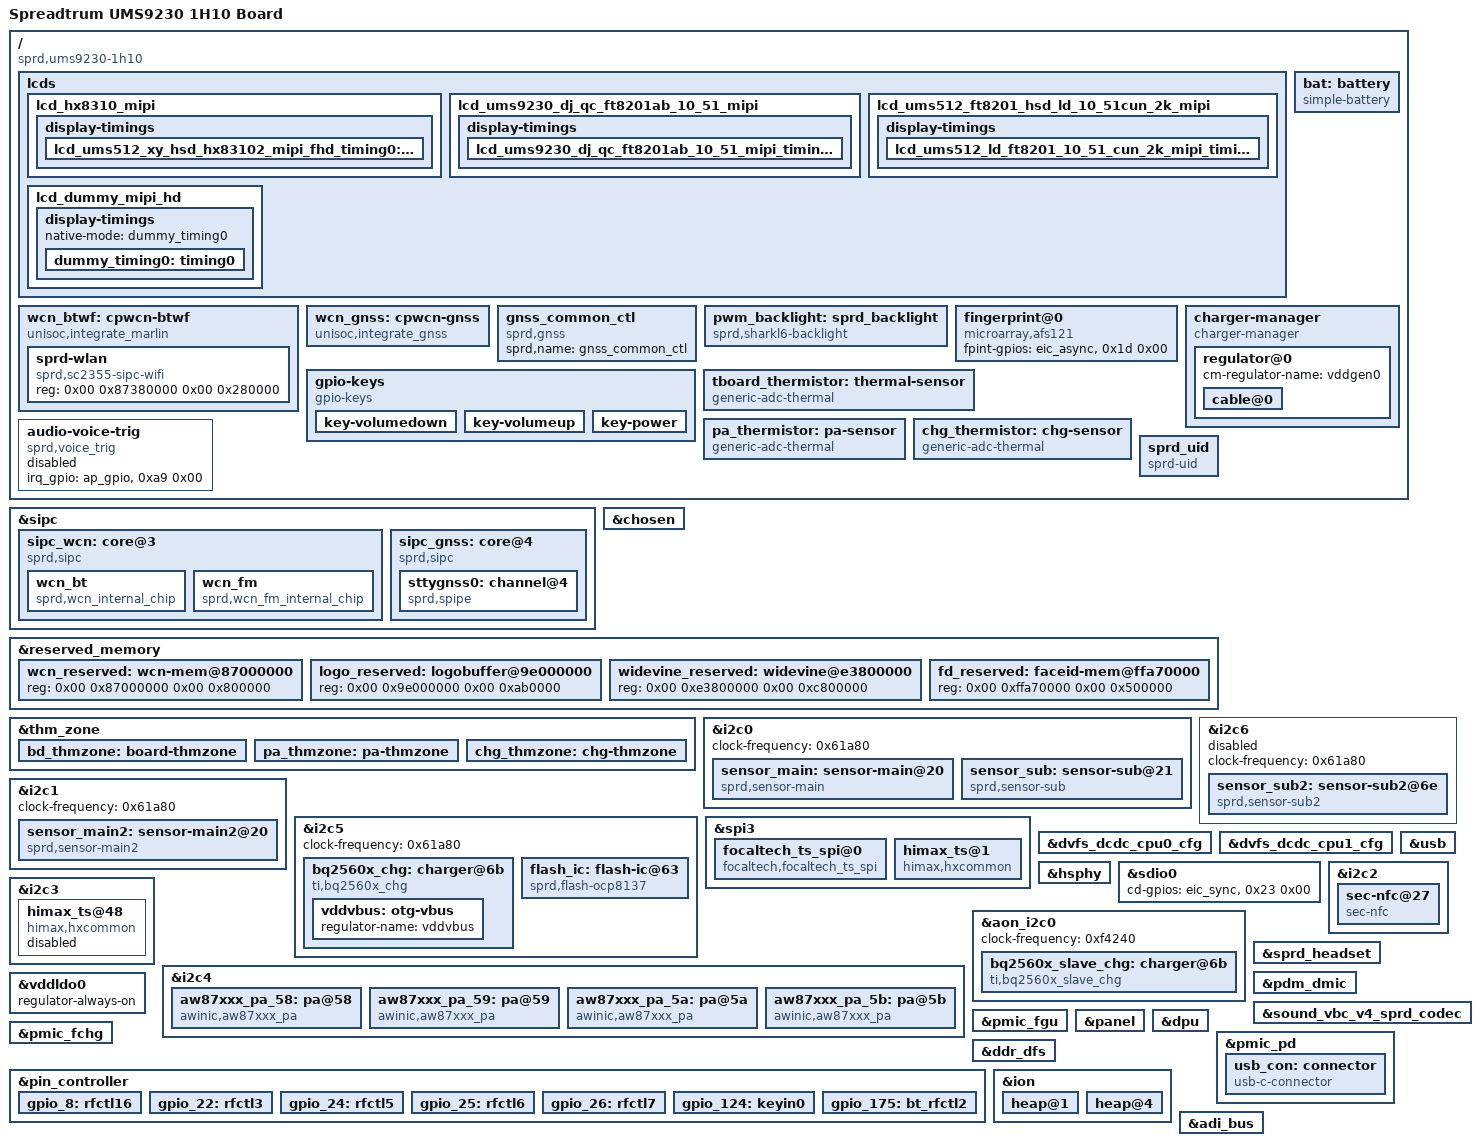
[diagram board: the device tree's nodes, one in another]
/dts-v1/;
/plugin/;

/ {
	model = "Spreadtrum UMS9230 1H10 Board";
	compatible = "sprd,ums9230-1h10";
	sprd,sc-id = "ums9230 1h10 1000";

	fragment {
		target-path = "/";

		__overlay__ {
			#address-cells = <0x02>;
			#size-cells = <0x02>;

			lcds {

				lcd_hx8310_mipi: lcd_hx8310_mipi {
					sprd,dsi-work-mode = <0x01>;
					sprd,dsi-lane-number = <0x04>;
					sprd,dsi-color-format = "rgb888";
					sprd,phy-bit-clock = <0xf32a0>;
					sprd,phy-escape-clock = <0x4e20>;
					sprd,width-mm = <0x87>;
					sprd,height-mm = <0xda>;
					sprd,esd-check-enable = <0x00>;
					sprd,esd-check-mode = <0x03>;
					sprd,esd-check-period = <0x3e8>;
					sprd,esd-check-register = <0x0a>;
					sprd,esd-check-value = <0x9c>;
					sprd,dpi-clk-div = <0x06>;
					sprd,video-lp-cmd-enable = <0x01>;
					sprd,hporch-lp-disable = <0x01>;
					sprd,use-dcs-write;
					sprd,reset-on-sequence = <0x01 0x0a 0x00 0x14 0x01 0x78>;
					sprd,reset-off-sequence = <0x00 0x14>;
					sprd,initial-command = [39 00 00 04 b9 83 10 2e 23 00 00 02 e2 03 23 00 00 02 e9 cd 23 00 00 02 bb 01 23 00 00 02 e9 00 39 00 00 05 d1 67 0c ff 05 39 00 00 12 b1 10 fa af af 31 31 b1 6b 31 36 36 36 36 22 21 15 00 39 00 00 11 b2 00 b0 47 80 00 26 e0 29 00 00 00 00 15 20 d7 00 39 00 00 11 b4 30 36 30 36 30 36 30 36 08 6f 07 58 00 ff 00 ff 39 00 00 03 d2 31 31 39 00 00 08 bf fc 85 80 9c 36 00 1c 39 00 00 2c d3 00 00 00 00 3c e8 00 00 00 37 37 33 0f 26 26 04 00 32 10 24 00 24 32 17 a8 07 a8 32 10 08 00 00 00 00 2b 50 b6 c8 2c 4f b6 c8 0f 39 00 00 2f e0 00 07 14 1b 23 40 58 5e 64 5f 76 7a 7d 8b 88 92 9c b2 b3 59 61 6c 73 00 07 14 1b 23 40 58 5e 64 5f 76 7a 7d 8b 88 92 9c b2 b3 59 61 6c 73 23 00 00 02 bd 01 39 00 00 0b cb 80 36 12 16 c0 28 40 84 02 34 39 00 00 0c d3 01 00 fc 00 00 11 10 00 0a 00 01 23 00 00 02 bd 02 39 00 00 07 b4 4e 00 33 11 33 88 39 00 00 04 bf f2 00 02 23 00 00 02 bd 00 39 00 00 0f c0 33 33 22 11 a2 17 00 80 00 00 08 00 63 63 39 00 00 2d d5 18 18 18 18 18 18 18 18 18 18 19 19 18 18 1a 1a 1b 1b 00 01 02 03 04 05 06 07 20 21 24 25 18 18 18 18 18 18 18 18 18 18 18 18 18 18 39 00 00 2d d6 18 18 18 18 18 18 18 18 18 18 18 18 19 19 1a 1a 1b 1b 07 06 05 04 03 02 01 00 25 24 21 20 18 18 18 18 18 18 18 18 18 18 18 18 18 18 39 00 00 04 d0 07 04 05 39 00 00 18 e7 12 13 02 02 55 00 0e 0e 00 26 29 72 1c 72 01 27 00 00 00 00 17 00 68 23 00 00 02 bd 01 39 00 00 08 e7 01 30 01 94 0d b5 0e 23 00 00 02 bd 02 39 00 00 1d e7 ff 01 fd 01 00 00 22 00 00 00 00 00 00 00 00 00 00 00 00 00 00 00 00 00 81 00 02 40 23 00 00 02 bd 00 39 00 00 0d d8 aa bb aa aa aa a0 aa bb aa aa aa a0 23 00 00 02 bd 02 39 00 00 0d d8 ff ff ff ff ff f0 ff ff ff ff ff f0 23 00 00 02 bd 03 39 00 00 19 d8 00 2a aa aa aa a0 00 2a aa aa aa a0 00 2a aa aa aa a0 00 2a aa aa aa a0 23 00 00 02 bd 00 39 00 00 09 ba 70 03 a8 83 f2 80 c0 0d 23 00 00 02 bd 03 23 00 00 02 b2 80 23 00 00 02 bd 00 39 00 00 07 c8 00 04 04 00 00 02 23 00 00 02 bd 00 39 00 00 06 cb 00 13 08 02 25 23 00 00 02 bd 02 39 00 00 06 cb 00 03 00 01 7e 23 00 00 02 bd 00 39 00 00 08 c7 30 b0 c2 08 10 42 04 23 00 00 02 bd 00 23 00 00 02 cc 0e 23 00 00 02 35 00 39 00 00 03 51 07 ff 39 00 00 04 c9 00 0e 10 23 00 00 02 53 2c 05 78 00 01 11 05 14 00 01 29];
					sprd,sleep-in-command = [13 0a 00 01 28 13 78 00 01 10];
					sprd,sleep-out-command = [13 78 00 01 11 13 64 00 01 29];
					phandle = <0x15>;

					display-timings {
						native-mode = <&lcd_ums512_xy_hsd_hx83102_mipi_fhd_timing0>;

						lcd_ums512_xy_hsd_hx83102_mipi_fhd_timing0: timing0 {
							clock-frequency = <0x9e4f580>;
							hactive = <0x4b0>;
							vactive = <0x780>;
							hback-porch = <0x10>;
							hfront-porch = <0x28>;
							vback-porch = <0x12>;
							vfront-porch = <0xe0>;
							hsync-len = <0x0c>;
							vsync-len = <0x0c>;
							phandle = <0x01>;
						};
					};
				};

				lcd_ums9230_dj_qc_ft8201ab_10_51_mipi: lcd_ums9230_dj_qc_ft8201ab_10_51_mipi {
					sprd,dsi-work-mode = <0x01>;
					sprd,dsi-lane-number = <0x04>;
					sprd,dsi-color-format = "rgb888";
					sprd,phy-bit-clock = <0xfee20>;
					sprd,phy-escape-clock = <0x4e20>;
					sprd,width-mm = <0x44>;
					sprd,height-mm = <0x79>;
					sprd,esd-check-enable = <0x00>;
					sprd,esd-check-mode = <0x03>;
					sprd,esd-check-period = <0x3e8>;
					sprd,esd-check-register = <0x0a>;
					sprd,esd-check-value = <0x9c>;
					sprd,dpi-clk-div = <0x06>;
					sprd,video-lp-cmd-enable = <0x01>;
					sprd,hporch-lp-disable = <0x01>;
					sprd,reset-on-sequence = <0x01 0x0a 0x00 0x14 0x01 0x64>;
					sprd,reset-off-sequence = <0x00 0x14>;
					sprd,use-dcs-write;
					sprd,initial-command = [23 00 00 02 00 00 39 00 00 04 ff 82 01 01 23 00 00 02 00 80 39 00 00 03 ff 82 01 23 00 00 02 00 93 23 00 00 02 c5 52 23 00 00 02 00 97 23 00 00 02 c5 52 23 00 00 02 00 9e 23 00 00 02 c5 05 23 00 00 02 00 9a 23 00 00 02 c5 e1 23 00 00 02 00 9c 23 00 00 02 c5 e1 23 00 00 02 00 b6 39 00 00 03 c5 43 43 23 00 00 02 00 b8 39 00 00 03 c5 57 57 23 00 00 02 00 00 39 00 00 03 d8 be be 23 00 00 02 00 00 39 00 00 04 d9 00 64 64 23 00 00 02 00 82 23 00 00 02 c5 95 23 00 00 02 00 83 23 00 00 02 c5 07 23 00 00 02 00 94 23 00 00 02 c5 46 23 00 00 02 00 98 23 00 00 02 c5 64 23 00 00 02 00 9b 23 00 00 02 c5 65 23 00 00 02 00 9d 23 00 00 02 c5 65 23 00 00 02 00 a0 23 00 00 02 a5 04 23 00 00 02 00 b0 39 00 00 04 ca 00 00 04 23 00 00 02 00 b4 23 00 00 02 ca 03 23 00 00 02 00 e6 23 00 00 02 c0 50 23 00 00 02 00 a7 23 00 00 02 f3 20 23 00 00 02 00 c1 23 00 00 02 c0 11 23 00 00 02 00 00 39 00 00 11 e1 05 0e 23 36 41 4d 5f 6e 71 7e 81 97 6c 59 5a 50 23 00 00 02 00 10 39 00 00 09 e1 49 3f 31 29 22 15 0d 13 23 00 00 02 00 00 39 00 00 11 e2 05 0e 23 36 41 4d 5f 6e 71 7e 81 97 6c 59 5a 50 23 00 00 02 00 10 39 00 00 09 e2 49 3f 31 29 22 15 0d 07 23 00 00 02 00 80 23 00 00 02 a4 8c 23 00 00 02 00 a0 23 00 00 02 f3 10 23 00 00 02 00 a1 39 00 00 03 b3 04 b0 23 00 00 02 00 a3 39 00 00 03 b3 07 80 23 00 00 02 00 a5 39 00 00 03 b3 80 13 23 00 00 02 00 d0 23 00 00 02 c1 b0 23 00 00 02 00 80 39 00 00 08 cb 3f 3f 3f 3f 3f 3f 3f 23 00 00 02 00 87 23 00 00 02 cb 3f 23 00 00 02 00 88 39 00 00 09 cb 3f 3f 3f 3f 3f 3f 3f 3f 23 00 00 02 00 90 39 00 00 08 cb 3f 3f 3f 3f 3f 3f 3f 23 00 00 02 00 97 23 00 00 02 cb 3f 23 00 00 02 00 98 39 00 00 09 cb d4 d4 d4 d4 d4 d4 d4 d4 23 00 00 02 00 a0 39 00 00 09 cb d4 d4 db d8 d4 d4 d4 d4 23 00 00 02 00 a8 39 00 00 09 cb d4 d4 d4 d4 d4 d4 d4 d4 23 00 00 02 00 b0 39 00 00 08 cb 00 00 00 00 00 00 00 23 00 00 02 00 b7 23 00 00 02 cb 00 23 00 00 02 00 b8 39 00 00 09 cb 00 00 00 00 00 00 00 00 23 00 00 02 00 c0 39 00 00 08 cb 00 00 00 00 00 00 00 23 00 00 02 00 c7 23 00 00 02 cb 00 23 00 00 02 00 d0 39 00 00 0b cb 00 00 30 30 00 30 30 30 00 30 23 00 00 02 00 80 39 00 00 09 cc 38 38 38 38 38 38 38 38 23 00 00 02 00 88 39 00 00 09 cc 2b 22 20 35 34 1a 18 16 23 00 00 02 00 90 39 00 00 07 cc 14 12 10 08 38 38 23 00 00 02 00 80 39 00 00 09 cd 38 38 38 38 38 38 38 38 23 00 00 02 00 88 39 00 00 09 cd 2b 21 1f 35 34 19 17 15 23 00 00 02 00 90 39 00 00 07 cd 13 11 0f 07 38 38 23 00 00 02 00 a0 39 00 00 09 cc 38 38 38 38 38 38 38 38 23 00 00 02 00 a8 39 00 00 09 cc 2b 21 07 35 34 0f 11 13 23 00 00 02 00 b0 39 00 00 07 cc 15 17 19 1f 38 38 23 00 00 02 00 a0 39 00 00 09 cd 38 38 38 38 38 38 38 38 23 00 00 02 00 a8 39 00 00 09 cd 2b 22 08 35 34 10 12 14 23 00 00 02 00 b0 39 00 00 07 cd 16 18 1a 20 38 38 23 00 00 02 00 81 23 00 00 02 c2 40 23 00 00 02 00 fd 23 00 00 02 cb 82 23 00 00 02 00 90 39 00 00 05 c2 85 03 1f 9f 23 00 00 02 00 94 39 00 00 05 c2 84 03 1f 9f 23 00 00 02 00 b0 39 00 00 05 c2 03 43 1f 9f 23 00 00 02 00 b4 39 00 00 05 c2 02 43 1f 9f 23 00 00 02 00 b8 39 00 00 05 c2 01 03 1f 9f 23 00 00 02 00 bc 39 00 00 05 c2 02 03 1f 9f 23 00 00 02 00 e0 39 00 00 09 c2 82 01 02 76 9f 00 00 0b 23 00 00 02 00 e8 39 00 00 09 c2 81 02 02 76 9f 00 00 0b 23 00 00 02 00 f0 39 00 00 09 c2 00 03 02 76 9f 00 00 0b 23 00 00 02 00 f8 39 00 00 09 c2 01 04 02 76 9f 00 00 0b 23 00 00 02 00 80 39 00 00 09 c3 02 05 02 76 9f 00 00 0b 23 00 00 02 00 88 39 00 00 09 c3 03 06 02 76 9f 00 00 0b 23 00 00 02 00 90 39 00 00 09 c3 04 07 02 76 9f 00 00 0b 23 00 00 02 00 98 39 00 00 09 c3 05 08 02 76 9f 00 00 0b 23 00 00 02 00 c0 39 00 00 09 cd 06 09 02 76 9f 00 00 0b 23 00 00 02 00 c8 39 00 00 09 cd 07 0a 02 76 9f 00 00 0b 23 00 00 02 00 d0 39 00 00 09 cd 08 0b 02 76 9f 00 00 0b 23 00 00 02 00 d8 39 00 00 09 cd 09 0c 02 76 9f 00 00 0b 23 00 00 02 00 f0 39 00 00 07 cc 3d 88 88 18 18 80 23 00 00 02 00 80 39 00 00 07 c0 00 96 01 0b 00 17 23 00 00 02 00 90 39 00 00 07 c0 00 96 01 0b 00 17 23 00 00 02 00 a0 39 00 00 07 c0 01 27 01 12 00 10 23 00 00 02 00 b0 39 00 00 06 c0 00 96 01 0b 17 23 00 00 02 00 a3 39 00 00 04 c1 22 22 04 23 00 00 02 00 80 23 00 00 02 ce 00 23 00 00 02 00 90 23 00 00 02 ce 00 23 00 00 02 00 d0 39 00 00 09 ce 01 00 18 01 01 00 ef 01 23 00 00 02 00 e0 23 00 00 02 ce 00 23 00 00 02 00 f0 23 00 00 02 ce 00 23 00 00 02 00 b0 39 00 00 05 cf 06 06 4c 50 23 00 00 02 00 b5 39 00 00 05 cf 03 03 bc c0 23 00 00 02 00 c0 39 00 00 05 cf 07 07 58 5c 23 00 00 02 00 c5 39 00 00 05 cf 00 07 08 80 23 00 00 02 00 90 23 00 00 02 c4 88 23 00 00 02 00 92 23 00 00 02 c4 c0 23 00 00 02 00 c5 39 00 00 04 c3 0e 00 10 23 00 00 02 00 c8 39 00 00 04 c3 0e 00 10 23 00 00 02 00 c9 23 00 00 02 ce 00 23 00 00 02 1c 00 23 00 00 02 00 d6 23 00 00 02 c1 00 23 00 00 02 00 d5 23 00 00 02 c0 f0 23 00 00 02 00 a0 23 00 00 02 c1 e0 23 00 00 02 00 9f 23 00 00 02 c5 00 23 00 00 02 00 91 23 00 00 02 c5 4c 23 00 00 02 00 d7 23 00 00 02 ce 01 23 00 00 02 00 82 23 00 00 02 a5 01 23 00 00 02 00 8c 39 00 00 03 cf 40 40 23 00 00 02 00 9a 23 00 00 02 f5 35 23 00 00 02 00 a2 23 00 00 02 f5 1f 23 00 00 02 00 b2 23 00 00 02 c5 15 23 00 00 02 00 b5 23 00 00 02 c5 05 23 00 00 02 00 d2 23 00 00 02 c5 d1 23 00 00 02 00 e0 39 00 00 05 c5 3c 3c fb fb 23 00 00 02 00 e8 39 00 00 05 c5 c1 14 09 07 23 00 00 02 00 ec 39 00 00 05 c5 00 00 00 00 23 00 00 02 00 f4 39 00 00 04 c5 00 01 01 23 00 00 02 00 fb 39 00 00 04 c5 01 01 01 23 00 00 02 00 f0 39 00 00 05 c5 3c 3c fb fb 23 00 00 02 00 f7 39 00 00 05 c5 3c 3c fb fb 23 00 00 02 00 a4 23 00 00 02 f3 0b 23 00 00 02 00 00 23 00 00 02 fa 02 23 00 00 02 00 a8 23 00 00 02 c5 09 23 00 00 02 00 cb 23 00 00 02 c5 01 23 00 00 02 00 b6 39 00 00 03 c5 43 43 23 00 00 02 00 b8 39 00 00 03 c5 57 57 23 00 00 02 00 91 23 00 00 02 a5 00 23 00 00 02 00 a4 23 00 00 02 f3 0b 23 00 00 02 00 00 23 00 00 02 fa 5a 23 00 00 02 00 a4 23 00 00 02 f3 0b 23 00 00 02 00 00 23 00 00 02 fa 01 23 00 00 02 00 a8 23 00 00 02 c5 09 23 00 00 02 00 cb 23 00 00 02 c5 09 23 00 00 02 00 b6 39 00 00 03 c5 41 41 23 00 00 02 00 b8 39 00 00 03 c5 55 55 23 00 00 02 00 91 23 00 00 02 a5 40 23 00 00 02 00 a4 23 00 00 02 f3 0b 23 00 00 02 00 00 23 00 00 02 fa 5a 23 00 00 02 00 00 39 00 00 04 ff 00 00 00 23 00 00 02 00 80 39 00 00 03 ff 00 00 13 78 00 01 11 13 14 00 01 29];
					sprd,sleep-in-command = [13 0a 00 01 28 13 78 00 01 10];
					sprd,sleep-out-command = [13 78 00 01 11 13 32 00 01 29];
					phandle = <0x16>;

					display-timings {
						native-mode = <&lcd_ums9230_dj_qc_ft8201ab_10_51_mipi_timing0>;

						lcd_ums9230_dj_qc_ft8201ab_10_51_mipi_timing0: timing0 {
							clock-frequency = <0xa5f0780>;
							hactive = <0x4b0>;
							vactive = <0x780>;
							hback-porch = <0x1c>;
							hfront-porch = <0x4c>;
							vback-porch = <0x28>;
							vfront-porch = <0xf4>;
							hsync-len = <0x08>;
							vsync-len = <0x06>;
							phandle = <0x02>;
						};
					};
				};

				lcd_ums512_ft8201_hsd_ld_10_51cun_2k_mipi: lcd_ums512_ft8201_hsd_ld_10_51cun_2k_mipi {
					sprd,dsi-work-mode = <0x01>;
					sprd,dsi-lane-number = <0x04>;
					sprd,dsi-color-format = "rgb888";
					sprd,phy-bit-clock = <0xe8e90>;
					sprd,phy-escape-clock = <0x4e20>;
					sprd,width-mm = <0x87>;
					sprd,height-mm = <0xda>;
					sprd,esd-check-enable = <0x00>;
					sprd,esd-check-mode = <0x03>;
					sprd,esd-check-period = <0x3e8>;
					sprd,esd-check-register = <0x0a>;
					sprd,esd-check-value = <0x9c>;
					sprd,dpi-clk-div = <0x06>;
					sprd,video-lp-cmd-enable = <0x01>;
					sprd,hporch-lp-disable = <0x01>;
					sprd,reset-on-sequence = <0x01 0x0a 0x00 0x14 0x01 0x64>;
					sprd,reset-off-sequence = <0x00 0x14>;
					sprd,use-dcs-write;
					sprd,initial-command = <0x23000002 0x3900 0x4ff82 0x1012300 0x20080 0x39000003 0xff820123 0x200 0x90390000 0xff54ad9 0x4ad92a2a 0x2b0b0c14 0x15393483 0x23000002 0xa03900 0xdf587 0x1618161f 0x97777746 0xc0d9e023 0x200 0x90390000 0x11c5840c 0x1664202 0x16b2701 0xcd25cd25 0x5402300 0x200d8 0x39000008 0xcd00000f 0xff000000 0x23000002 0xc42300 0x2cf00 0x23000002 0xc92300 0x2cf00 0x23000002 0x932300 0x2c57a 0x23000002 0x972300 0x2c57a 0x23000002 0x9e2300 0x2c50a 0x23000002 0x9a2300 0x2c539 0x23000002 0x9c2300 0x2c539 0x23000002 0xb63900 0x3c56b 0x6b230000 0x200b839 0x3c5 0x2f2f2300 0x20000 0x39000003 0xd8b4b423 0x200 0x82230000 0x2c59523 0x200 0x83230000 0x2c50723 0x200 0x390000 0x11e1050f 0x2437414d 0x5e6b6d78 0x798b7b6a 0x6b5f2300 0x20010 0x39000009 0xe1574b3b 0x31291906 0x230000 0x2000039 0x11e2 0x50f2437 0x414d5e6b 0x6d78798b 0x7b6a6b5f 0x23000002 0x103900 0x9e257 0x4b3b3129 0x19060023 0x200 0x80230000 0x2a40c23 0x200 0x84390000 0x3c50000 0x23000002 0xa02300 0x2f310 0x23000002 0xa13900 0x3b304 0xb0230000 0x200a339 0x3b3 0x7802300 0x200a5 0x39000003 0xb3801323 0x200 0xd0230000 0x2c1b023 0x200 0x80390000 0x8cb3333 0x30333033 0x30230000 0x2008723 0x2cb 0x33230000 0x2008839 0x9cb 0x33335555 0x33303333 0x23000002 0x903900 0x8cb30 0x33333330 0x30332300 0x20097 0x23000002 0xcb332300 0x20098 0x39000009 0xcb141414 0x14141414 0x14230000 0x200a039 0x9cb 0x14145555 0x14141414 0x23000002 0xa83900 0x9cb14 0x55551414 0x14141423 0x200 0xb0390000 0x8cb0000 0x00 0x230000 0x200b723 0x2cb 0x230000 0x200b839 0x9cb 0x5555 0x00 0x23000002 0xc03900 0x8cb00 0x55550000 0x2300 0x200c7 0x23000002 0xcb002300 0x20080 0x39000009 0xcc000000 0x292a 0x34230000 0x2008839 0x9cc 0x35131415 0x16071f00 0x23000002 0x903900 0x7cc00 0x00 0x230000 0x2008039 0x9cd 0x00 0x292a34 0x23000002 0x883900 0x9cd35 0x1718191a 0x8200023 0x200 0x90390000 0x7cd0000 0x00 0x23000002 0xa03900 0x9cc00 0x00 0x292a3423 0x200 0xa8390000 0x9cc351a 0x19181720 0x8002300 0x200b0 0x39000007 0xcc000000 0x23 0x200 0xa0390000 0x9cd0000 0x29 0x2a342300 0x200a8 0x39000009 0xcd351615 0x14131f07 0x230000 0x200b039 0x7cd 0x00 0x2300 0x20081 0x23000002 0xc2402300 0x20090 0x39000005 0xc2840278 0x9d230000 0x2009439 0x5c2 0x8302789d 0x23000002 0xb03900 0x5c200 0x2789d23 0x200 0xb4390000 0x5c20102 0x789d2300 0x20080 0x39000009 0xc3828702 0x7cb20002 0x7230000 0x2008839 0x9c3 0x85027c 0xb2000207 0x23000002 0x903900 0x9c302 0x83027cb2 0x20723 0x200 0x98390000 0x9c30481 0x27cb200 0x2072300 0x200c0 0x39000009 0xcd818602 0x7cb20002 0x7230000 0x200c839 0x9cd 0x184027c 0xb2000207 0x23000002 0xd03900 0x9cd03 0x82027cb2 0x20723 0x200 0xd8390000 0x9cd0580 0x27cb200 0x2072300 0x200e2 0x39000005 0xcc087c00 0x8230000 0x200f039 0x6cc 0x3d8888c0 0x230000 0x200fd23 0x2cb 0x82230000 0x2008039 0x7c0 0x9900f2 0x102300 0x20090 0x39000007 0xc0009900 0xf2001023 0x200 0xa0390000 0x7c00130 0xf20010 0x23000002 0xb03900 0x6c000 0x9900f210 0x23000002 0xa33900 0x4c128 0x28042300 0x20080 0x23000002 0xce002300 0x20090 0x23000002 0xce002300 0x200d0 0x39000009 0xce01000a 0x10100ea 0x1230000 0x200e023 0x2ce 0x230000 0x200f023 0x2ce 0x230000 0x200b039 0x5cf 0x606565a 0x23000002 0xb53900 0x5cf03 0x3d8dc23 0x200 0xc0390000 0x5cf0707 0x585c2300 0x200c5 0x39000005 0xcf000708 0x80230000 0x2009023 0x2c4 0x88230000 0x2009223 0x2c4 0xc0230000 0x200c839 0x4c3 0xfff00023 0x200 0xc0390000 0xcc50000 0xf0f 0xf0f000c 0x230000 0x200c923 0x2ce 0x230000 0x21c0023 0x200 0xd6230000 0x2c10023 0x200 0xd5230000 0x2c0f023 0x200 0xa0230000 0x2c1e023 0x200 0x9f230000 0x2c50023 0x200 0x91230000 0x2c54c23 0x200 0xd7230000 0x2ce0123 0x200 0x94230000 0x2c54623 0x200 0x98230000 0x2c56423 0x200 0x9b230000 0x2c56523 0x200 0x9d230000 0x2c56523 0x200 0x82230000 0x2a50123 0x200 0x8c390000 0x3cf4040 0x23000002 0x9a2300 0x2f535 0x23000002 0xa22300 0x2f51f 0x23000002 0xb62300 0x2c002 0x23000002 0xa02300 0x2a504 0x23000002 0xc12300 0x2c011 0x23000002 0xa42300 0x2f30b 0x23000002 0x2300 0x2fa02 0x23000002 0xa82300 0x2c509 0x23000002 0xcb2300 0x2c501 0x23000002 0xb63900 0x3c56b 0x6b230000 0x200b839 0x3c5 0x2f2f2300 0x20091 0x23000002 0xa5002300 0x200a4 0x23000002 0xf30b2300 0x20000 0x23000002 0xfa5a2300 0x200a4 0x23000002 0xf30b2300 0x20000 0x23000002 0xfa012300 0x200a8 0x23000002 0xc5092300 0x200cb 0x23000002 0xc5092300 0x200b6 0x39000003 0xc5696923 0x200 0xb8390000 0x3c52d2d 0x23000002 0x912300 0x2a540 0x23000002 0xa42300 0x2f30b 0x23000002 0x2300 0x2fa5a 0x23000002 0xe62300 0x2c050 0x23000002 0xa72300 0x2f320 0x23780002 0x11002314 0x22900>;
					sprd,sleep-in-command = [13 0a 00 01 28 13 78 00 01 10];
					sprd,sleep-out-command = [13 78 00 01 11 13 32 00 01 29];
					phandle = <0x17>;

					display-timings {
						native-mode = <&lcd_ums512_ld_ft8201_10_51_cun_2k_mipi_timing0>;

						lcd_ums512_ld_ft8201_10_51_cun_2k_mipi_timing0: timing0 {
							clock-frequency = <0x97a25c0>;
							hactive = <0x4b0>;
							vactive = <0x780>;
							hback-porch = <0x06>;
							hfront-porch = <0x06>;
							vback-porch = <0x1c>;
							vfront-porch = <0xe0>;
							hsync-len = <0x04>;
							vsync-len = <0x06>;
							phandle = <0x03>;
						};
					};
				};

				lcd_dummy_mipi_hd: lcd_dummy_mipi_hd {
					sprd,dsi-work-mode = <0x01>;
					sprd,dsi-lane-number = <0x04>;
					sprd,dsi-color-format = "rgb888";
					sprd,initial-command = [13 78 00 01 11 13 64 00 01 29];
					sprd,sleep-in-command = [13 0a 00 01 28 13 78 00 01 10];
					sprd,sleep-out-command = [13 78 00 01 11 13 64 00 01 29];
					phandle = <0x18>;

					display-timings {
						native-mode = <&dummy_timing0>;

						dummy_timing0: timing0 {
							clock-frequency = <0x493e000>;
							hactive = <0x2d0>;
							vactive = <0x500>;
							hback-porch = <0x3c>;
							hfront-porch = <0x50>;
							vback-porch = <0x0c>;
							vfront-porch = <0x26>;
							hsync-len = <0x3c>;
							vsync-len = <0x04>;
							phandle = <0x04>;
						};
					};
				};
			};

			wcn_btwf: cpwcn-btwf {
				compatible = "unisoc,integrate_marlin";
				sprd,name = "wcn_btwf";
				sprd,syscon-ap-apb = <&aon_apb_regs>;
				sprd,syscon-ap-pmu = <&pmu_apb_regs>;
				sprd,syscon-wcn-aon-apb = <&wcncp_aon_apb_regs>;
				sprd,syscon-wcn-aon-ahb = <&wcncp_aon_ahb_regs>;
				sprd,syscon-ap-pub-apb = <&pub_apb_regs>;
				sprd,syscon-wcn-btwf-ahb = <&wcncp_btwf_ahb_regs>;
				sprd,ctrl-probe-num = <0x01>;
				sprd,ctrl-reg = <0x9018 0x23a8 0x2818 0x23a8 0x90 0x98 0x0c 0x1410 0x4c 0x0c>;
				sprd,ctrl-mask = <0x3fff 0x2000000 0x80 0x1000000 0x40000000 0x100f 0x55 0x3000000 0xffffffff 0x55>;
				sprd,ctrl-value = <0x70 0x2000000 0x80 0x1000000 0x40000000 0x00 0x55 0x3000000 0x7fdc00 0x00>;
				sprd,ctrl-rw-offset = <0x1000 0x2000 0x2000 0x2000 0x00 0x00 0x00 0x1000 0x00 0x00>;
				sprd,ctrl-us-delay = <0x3e8 0x3e8 0x3e8 0x7d0 0x3e8 0x3e8 0x3e8 0x3e8 0x3e8 0x3e8>;
				sprd,ctrl-type = <0x02 0x01 0x01 0x01 0x0a 0x0a 0x09 0x07 0x09 0x09>;
				sprd,ctrl-shutdown-reg = <0x98>;
				sprd,ctrl-shutdown-mask = <0x1000>;
				sprd,ctrl-shutdown-value = <0x1000>;
				sprd,ctrl-shutdown-rw-offset = <0x00>;
				sprd,ctrl-shutdown-us-delay = <0x0a>;
				sprd,ctrl-shutdown-type = <0x0a>;
				reg = <0x00 0x87000000 0x00 0x200000 0x00 0x87210000 0x00 0x2800 0x00 0x7c00a000 0x00 0x74>;
				sprd,file-name = "/dev/block/platform/soc/soc:ap-apb/201d0000.sdio/by-name/wcnmodem";
				sprd,file-name-ufs = "/dev/block/platform/soc/soc:ap-apb/20200000.ufs/by-name/wcnmodem";
				sprd,firmware-path = "/vendor/firmware/";
				sprd,file-length = <0x200000>;
				sprd,apcp-sync-addr = <0x7fdc00>;
				sprd,wcn-sipc-ver = <0x01>;
				vddwcn-supply = <&vddwcn>;
				dcxo1v8-supply = <&vddsim2>;
				vddwifipa-supply = <&vddwifipa>;
				merlion-chip-en-gpios = <&ap_gpio>, <0x76 0x00>;
				merlion-rst-gpios = <&ap_gpio>, <0x75 0x00>;
				xtal-26m-type-sel-gpios = <&ap_gpio>, <0xad 0x00>;
				nvmem-cells = <&wcn_alpha>;
				nvmem-cell-names = "wcn_efuse_blk0";
				#address-cells = <0x02>;
				#size-cells = <0x02>;
				phandle = <0x19>;

				sprd-wlan {
					compatible = "sprd,sc2355-sipc-wifi";
					reg = <0x00 0x87380000 0x00 0x280000>;
				};
			};

			wcn_gnss: cpwcn-gnss {
				compatible = "unisoc,integrate_gnss";
				sprd,name = "wcn_gnss";
				sprd,syscon-ap-apb = <&aon_apb_regs>;
				sprd,syscon-ap-pmu = <&pmu_apb_regs>;
				sprd,syscon-wcn-aon-apb = <&wcncp_aon_apb_regs>;
				sprd,syscon-wcn-aon-ahb = <&wcncp_aon_ahb_regs>;
				sprd,syscon-ap-pub-apb = <&pub_apb_regs>;
				sprd,syscon-wcn-gnss-ahb = <&wcncp_gnss_ahb_regs>;
				sprd,ctrl-probe-num = <0x01>;
				sprd,ctrl-reg = <0x9018 0x23a8 0x2818 0x23a8 0x90 0xc8 0x0c 0x1404 0x50 0x0c>;
				sprd,ctrl-mask = <0x3fff 0x2000000 0x80 0x1000000 0x40000000 0x100f 0x22 0x1ffffff 0xffffffff 0x22>;
				sprd,ctrl-value = <0x70 0x2000000 0x80 0x1000000 0x40000000 0x00 0x22 0x1600000 0x1ffc00 0x00>;
				sprd,ctrl-rw-offset = <0x1000 0x2000 0x2000 0x2000 0x00 0x00 0x00 0x1000 0x00 0x00>;
				sprd,ctrl-us-delay = <0x3e8 0x3e8 0x3e8 0x7d0 0x3e8 0x3e8 0x3e8 0x3e8 0x3e8 0x3e8>;
				sprd,ctrl-type = <0x02 0x01 0x01 0x01 0x0a 0x0a 0x09 0x08 0x09 0x09>;
				sprd,ctrl-shutdown-reg = <0xc8>;
				sprd,ctrl-shutdown-mask = <0x1000>;
				sprd,ctrl-shutdown-value = <0x1000>;
				sprd,ctrl-shutdown-rw-offset = <0x00>;
				sprd,ctrl-shutdown-us-delay = <0x0a>;
				sprd,ctrl-shutdown-type = <0x0a>;
				reg = <0x00 0x87600000 0x00 0x180000>;
				sprd,file-name = "/dev/block/platform/soc/soc:ap-apb/201d0000.sdio/by-name/gnssmodem";
				sprd,file-name-ext = "/dev/block/platform/soc/soc:ap-apb/201d0000.sdio/by-name/gnssmodem";
				sprd,file-name-ufs = "/dev/block/platform/soc/soc:ap-apb/20200000.ufs/by-name/gnssmodem";
				sprd,file-name-ext-ufs = "/dev/block/platform/soc/soc:ap-apb/20200000.ufs/by-name/gnssmodem";
				sprd,file-length = <0x180000>;
				sprd,apcp-sync-addr = <0x1ffc00>;
				sprd,wcn-sipc-ver = <0x01>;
				vddwcn-supply = <&vddwcn>;
				dcxo1v8-supply = <&vddsim2>;
				merlion-chip-en-gpios = <&ap_gpio>, <0x76 0x00>;
				merlion-rst-gpios = <&ap_gpio>, <0x75 0x00>;
				xtal-26m-type-sel-gpios = <&ap_gpio>, <0xad 0x00>;
				#address-cells = <0x01>;
				#size-cells = <0x01>;
				nvmem-cells = <&wcn_alpha>;
				nvmem-cell-names = "gnss_efuse_blk0";
				phandle = <0x1a>;
			};

			gnss_common_ctl {
				compatible = "sprd,gnss";
				sprd,name = "gnss_common_ctl";
			};

			pwm_backlight: sprd_backlight {
				compatible = "sprd,sharkl6-backlight";
				pwms = <&pwms>, <0x02 0x9c40>;
				hall-gpio = <&ap_gpio>, <0x84 0x01>;
				pwm-names = "backlight";
				sprd,max-brightness-level = <0x39c>;
				default-brightness-level = <0x106>;
				sprd,brightness-scale = <0x3ff>;
				brightness-levels = <0x19 0x1a 0x1b 0x1c 0x1d 0x1e 0x1f 0x20 0x21 0x22 0x23 0x25 0x27 0x29 0x2b 0x2d 0x30 0x33 0x36 0x39 0x3c 0x3f 0x42 0x45 0x48 0x4b 0x4e 0x51 0x54 0x57 0x5a 0x5d 0x60 0x63 0x66 0x69 0x6c 0x6f 0x72 0x75 0x78 0x7b 0x7e 0x81 0x84 0x87 0x8a 0x8d 0x90 0x93 0x96 0x99 0x9c 0x9f 0xa2 0xa5 0xa8 0xab 0xae 0xb1 0xb4 0xb7 0xba 0xbd 0xc0 0xc3 0xc6 0xc9 0xcc 0xcf 0xd2 0xd5 0xd8 0xdb 0xde 0xe1 0xe4 0xe7 0xea 0xed 0xf0 0xf3 0xf6 0xf9 0xfc 0xff 0x102 0x105 0x108 0x10b 0x10e 0x111 0x114 0x117 0x11a 0x11d 0x120 0x124 0x128 0x12c 0x130 0x134 0x138 0x13c 0x140 0x144 0x148 0x14c 0x150 0x154 0x158 0x15c 0x160 0x164 0x168 0x16c 0x170 0x174 0x178 0x17c 0x180 0x184 0x188 0x18c 0x190 0x194 0x198 0x19c 0x1a0 0x1a4 0x1a8 0x1ac 0x1b0 0x1b4 0x1b8 0x1bc 0x1c0 0x1c4 0x1c8 0x1cc 0x1d0 0x1d4 0x1d8 0x1dc 0x1e0 0x1e4 0x1e8 0x1ec 0x1f0 0x1f4 0x1f8 0x1fc 0x200 0x204 0x208 0x20c 0x210 0x214 0x218 0x21c 0x220 0x224 0x228 0x22c 0x230 0x234 0x238 0x23c 0x240 0x244 0x248 0x24c 0x250 0x254 0x258 0x25c 0x260 0x264 0x268 0x26c 0x270 0x274 0x278 0x27c 0x280 0x284 0x288 0x28c 0x290 0x294 0x298 0x29c 0x2a0 0x2a4 0x2a8 0x2ac 0x2b0 0x2b4 0x2b8 0x2bc 0x2c0 0x2c4 0x2c8 0x2cc 0x2d0 0x2d4 0x2d8 0x2dc 0x2e0 0x2e4 0x2e8 0x2ec 0x2f0 0x2f4 0x2f8 0x2fc 0x300 0x304 0x308 0x30c 0x310 0x314 0x318 0x31c 0x320 0x324 0x328 0x32c 0x330 0x334 0x338 0x33c 0x340 0x344 0x348 0x34c 0x350 0x354 0x358 0x35c 0x360 0x364 0x368 0x36c 0x370 0x374 0x378 0x37c 0x380 0x384 0x388 0x38c 0x390 0x394 0x398 0x39c>;
				phandle = <0x0a>;
			};

			fingerprint@0 {
				compatible = "microarray,afs121";
				fpint-gpios = <&eic_async>, <0x1d 0x00>;
			};

			gpio-keys {
				compatible = "gpio-keys";

				key-volumedown {
					label = "Volume Down Key";
					linux,code = <0x72>;
					gpios = <&ap_gpio>, <0x7c 0x01>;
					debounce-interval = <0x02>;
					wakeup-source;
				};

				key-volumeup {
					label = "Volume Up Key";
					linux,code = <0x73>;
					gpios = <&ap_gpio>, <0x7d 0x01>;
					debounce-interval = <0x02>;
					wakeup-source;
				};

				key-power {
					label = "Power Key";
					linux,code = <0x74>;
					gpios = <&pmic_eic>, <0x01 0x01>;
					debounce-interval = <0x02>;
					wakeup-source;
				};
			};

			bat: battery {
				compatible = "simple-battery";
				charge-full-design-microamp-hours = <0x73f780>;
				charge-term-current-microamp = <0xea60>;
				constant-charge-voltage-max-microvolt = <0x43bfc0>;
				fullbatt-voltage-offset-microvolt = <0xafc8>;
				factory-internal-resistance-micro-ohms = <0x12cc8>;
				voltage-min-design-microvolt = <0x34a490>;
				fast-charge-threshold-microvolt = <0x3e8fa0>;
				fullbatt-voltage = <0x41c3f0>;
				fullbatt-current = <0x68fb0>;
				first-fullbatt-current = <0x445c0>;
				fullbatt-track-end-vol = <0x41c3f0>;
				fullbatt-track-end-cur = <0x68fb0>;
				first-calib-voltage = <0x362b30>;
				first-calib-capacity = <0x32>;
				ir-us-upper-limit-microvolt = <0x44aa20>;
				ir-cv-offset-microvolt = <0x186a0>;
				ir-rc-micro-ohms = <0x4e20>;
				ocv-capacity-celsius = <0x14>;
				ocv-capacity-table-0 = <0x41eee8 0x64 0x412b98 0x5f 0x403d50 0x5a 0x3f7a00 0x55 0x3ea328 0x50 0x3df360 0x4b 0x3cf578 0x46 0x3c93d0 0x41 0x3bfb78 0x3c 0x3b4bb0 0x37 0x3ac6e0 0x32 0x3a6920 0x2d 0x3a22d0 0x28 0x39e450 0x23 0x39b188 0x1e 0x3976f0 0x19 0x391160 0x14 0x387cf0 0x0f 0x37c170 0x0a 0x367950 0x05 0x3519c0 0x00>;
				voltage-temp-table = <0x12f390 0x2ee 0x1145e0 0x320 0xf9830 0x352 0xd84f0 0x384 0xc40b8 0x3b6 0xa8b38 0x3e8 0x94700 0x41a 0x7d000 0x44c 0x6d600 0x47e 0x5bcc0 0x4b0 0x4f588 0x4e2 0x43df0 0x514 0x39dc8 0x546 0x318f8 0x578 0x2ab98 0x5aa 0x24220 0x5dc 0x1f400 0x60e 0x1ccf0 0x640>;
				capacity-temp-table = <0x2d 0x64 0x19 0x64 0x0a 0x5f 0x00 0x4e 0xfffffff6 0x3c>;
				resistance-temp-table = <0x2d 0x35 0x19 0x64 0x0a 0x18b 0x00 0x237 0xfffffff6 0x319>;
				charge-sdp-current-microamp = <0x1e8480 0x1e8480>;
				charge-dcp-current-microamp = <0x1e8480 0x1e8480>;
				charge-cdp-current-microamp = <0x1e8480 0x1e8480>;
				charge-unknown-current-microamp = <0x1e8480 0x1e8480>;
				charge-fchg-current-microamp = <0x319750 0x1e8480>;
				energy-desity-ocv-table = <0x331df0 0x39fbc0 0x3f52f0 0x426030>;
				dcp-jeita-temp-table = <0x3e8 0x406 0x00 0x43bfc0 0x47e 0x49c 0x1e8480 0x43bfc0 0x5c8 0x5aa 0x1e8480 0x43bfc0 0x622 0x604 0x1e8480 0x43bfc0>;
				sdp-jeita-temp-table = <0x3e8 0x406 0x00 0x43bfc0 0x47e 0x49c 0x1e8480 0x43bfc0 0x5c8 0x5aa 0x1e8480 0x43bfc0 0x622 0x604 0x1e8480 0x43bfc0>;
				cdp-jeita-temp-table = <0x3e8 0x406 0x00 0x43bfc0 0x47e 0x49c 0x1e8480 0x43bfc0 0x5c8 0x5aa 0x1e8480 0x43bfc0 0x622 0x604 0x1e8480 0x43bfc0>;
				unknown-jeita-temp-table = <0x3e8 0x406 0x00 0x43bfc0 0x47e 0x49c 0x1e8480 0x43bfc0 0x5c8 0x5aa 0x1e8480 0x43bfc0 0x622 0x604 0x1e8480 0x43bfc0>;
				fchg-jeita-temp-table = <0x3e8 0x406 0x00 0x43bfc0 0x47e 0x49c 0x319750 0x43bfc0 0x5c8 0x5aa 0x319750 0x43bfc0 0x622 0x604 0x200b20 0x43bfc0>;
				flash-jeita-temp-table = <0x3e8 0x3fc 0x00 0x43bfc0 0x41a 0x42e 0x7a120 0x43bfc0 0x460 0x474 0xf4240 0x43bfc0 0x488 0x49c 0x1e8480 0x43bfc0 0x4c4 0x4d8 0x44aa20 0x43bfc0 0x53c 0x550 0x4c4b40 0x43bfc0 0x55a 0x546 0x4c4b40 0x43bfc0 0x578 0x564 0x44aa20 0x43bfc0 0x58c 0x578 0x40d990 0x43bfc0 0x5aa 0x596 0x3d0900 0x43bfc0 0x622 0x604 0xf4240 0x43bfc0>;
				wl-bpp-jeita-temp-table = <0x3e8 0x406 0x00 0x43bfc0 0x47e 0x49c 0x7a120 0x43bfc0 0x5c8 0x5aa 0xf4240 0x43bfc0 0x622 0x604 0x4c4b40 0x43bfc0>;
				wl-epp-jeita-temp-table = <0x3e8 0x406 0x00 0x43bfc0 0x47e 0x49c 0x1e8480 0x43bfc0 0x5c8 0x5aa 0x1e8480 0x43bfc0 0x622 0x604 0x1e8480 0x43bfc0>;
				force-jeita-status = <0x02>;
				phandle = <0x05>;
			};

			charger-manager {
				compatible = "charger-manager";
				cm-name = "battery";
				cm-poll-mode = <0x02>;
				cm-poll-interval = <0x3a98>;
				cm-battery-stat = <0x02>;
				cm-fullbatt-vchkdrop-ms = <0x7530>;
				cm-fullbatt-vchkdrop-volt = <0xea60>;
				cm-fullbatt-capacity = <0x64>;
				cm-cp-taper-current = <0xf4240>;
				cm-num-chargers = <0x02>;
				cm-num-fast-chargers = <0x01>;
				cm-num-wireless-chargers = <0x01>;
				cm-num-wireless-charge-pump-converters = <0x01>;
				cm-chargers = "bq2560x_charger", "bq2560x_slave_charger";
				cm-fast-chargers = "sc2730_fast_charger";
				cm-fuel-gauge = "sc27xx-fgu";
				cm-battery-cold = <0xc8>;
				cm-battery-cold-in-minus;
				cm-battery-hot = <0x320>;
				cm-battery-temp-diff = <0x64>;
				cm-charging-max = <0x1499700>;
				cm-discharging-max = <0x2932e0>;
				cm-wdt-interval = <0x3c>;
				cm-shutdown-voltage = <0x2f4d60>;
				cm-tickle-time-out = <0x190>;
				cm-one-cap-time = <0x3c>;
				cm-charge-voltage-max = <0x632ea0>;
				cm-fast-charge-voltage-max = <0xa037a0>;
				cm-flash-charge-voltage-max = <0xb71b00>;
				cm-wireless-charge-voltage-max = <0x632ea0>;
				cm-wireless-fast-charge-voltage-max = <0xb71b00>;
				cm-charge-voltage-drop = <0xaae60>;
				cm-fast-charge-voltage-drop = <0xaae60>;
				cm-flash-charge-voltage-drop = <0xf4240>;
				cm-cap-remap-table = <0x01 0x02 0x02 0x03 0x06 0x01 0x62 0x63 0x02 0x63 0x64 0x02>;
				monitored-battery = <&bat>;

				regulator@0 {
					cm-regulator-name = "vddgen0";

					cable@0 {
						cm-cable-name = "USB";
						extcon = <&pmic_typec>;
					};
				};
			};

			tboard_thermistor: thermal-sensor {
				compatible = "generic-adc-thermal";
				#thermal-sensor-cells = <0x00>;
				io-channels = <&pmic_adc>, <0x01>;
				io-channel-names = "sensor-channel";
				temperature-lookup-table = <0xffff64c2 0x46b 0xffff8baf 0x456 0xffffb3e8 0x432 0xffffedb9 0x3d7 0x277e 0x346 0x60e5 0x28e 0xaf7a 0x19d 0xd677 0x13c 0xfd7f 0xee 0x12484 0xb2 0x14b93 0x85 0x172a3 0x64 0x199b0 0x4b 0x1c0c9 0x39 0x1e7c8 0x2b>;
				phandle = <0x06>;
			};

			pa_thermistor: pa-sensor {
				compatible = "generic-adc-thermal";
				#thermal-sensor-cells = <0x00>;
				io-channels = <&pmic_adc>, <0x02>;
				io-channel-names = "sensor-channel";
				temperature-lookup-table = <0xffff64c2 0x46b 0xffff8baf 0x456 0xffffb3e8 0x432 0xffffedb9 0x3d7 0x277e 0x346 0x60e5 0x28e 0xaf7a 0x19d 0xd677 0x13c 0xfd7f 0xee 0x12484 0xb2 0x14b93 0x85 0x172a3 0x64 0x199b0 0x4b 0x1c0c9 0x39 0x1e7c8 0x2b>;
				phandle = <0x07>;
			};

			chg_thermistor: chg-sensor {
				compatible = "generic-adc-thermal";
				#thermal-sensor-cells = <0x00>;
				io-channels = <&pmic_adc>, <0x04>;
				io-channel-names = "sensor-channel";
				temperature-lookup-table = <0xffff64c2 0x46b 0xffff8baf 0x456 0xffffb3e8 0x432 0xffffedb9 0x3d7 0x277e 0x346 0x60e5 0x28e 0xaf7a 0x19d 0xd677 0x13c 0xfd7f 0xee 0x12484 0xb2 0x14b93 0x85 0x172a3 0x64 0x199b0 0x4b 0x1c0c9 0x39 0x1e7c8 0x2b>;
				phandle = <0x08>;
			};

			audio-voice-trig {
				status = "disable";
				compatible = "sprd,voice_trig";
				irq_gpio = <&ap_gpio>, <0xa9 0x00>;
			};

			sprd_uid {
				compatible = "sprd-uid";
				nvmem-cells = <&uid_start>, <&uid_end>;
				nvmem-cell-names = "uid_start", "uid_end";
			};
		};
	};

	fragment@0 {
		target = <&sipc>;

		__overlay__ {
			#address-cells = <0x01>;
			#size-cells = <0x00>;

			sipc_wcn: core@3 {
				compatible = "sprd,sipc";
				reg = <0x03>;
				label = "sipc-wcn";
				mboxes = <&mailbox>, <0x08 0x00>;
				sprd,smem-info = <0x87240000 0x240000 0x140000>;
				phandle = <0x1b>;

				wcn_bt {
					compatible = "sprd,wcn_internal_chip";
					sprd,name = "ttyBT";
					sprd,dst = <0x03>;
					sprd,channel = <0x04>;
					sprd,tx_bufid = <0x0b>;
					sprd,rx_bufid = <0x0a>;
				};

				wcn_fm {
					compatible = "sprd,wcn_fm_internal_chip";
					sprd,name = "fm";
					sprd,dst = <0x03>;
					sprd,tx_channel = <0x04>;
					sprd,rx_channel = <0x04>;
					sprd,tx_bufid = <0x0e>;
					sprd,rx_bufid = <0x0d>;
				};
			};

			sipc_gnss: core@4 {
				compatible = "sprd,sipc";
				#address-cells = <0x01>;
				#size-cells = <0x00>;
				reg = <0x04>;
				label = "sipc-gnss";
				mboxes = <&mailbox>, <0x09 0x00>;
				sprd,smem-info = <0x8749b000 0x11b000 0x32000>;
				phandle = <0x1c>;

				sttygnss0: channel@4 {
					compatible = "sprd,spipe";
					reg = <0x04>;
					label = "sttygnss0";
					sprd,ringnr = <0x01>;
					sprd,size-rxbuf = <0x19000>;
					sprd,size-txbuf = <0xc800>;
					phandle = <0x1d>;
				};
			};
		};
	};

	fragment@1 {
		target = <&chosen>;

		__overlay__ {
			bootargs_ext = "androidboot.hardware=ums9230_1h10 androidboot.dtbo_idx=0";
		};
	};

	fragment@2 {
		target = <&reserved_memory>;

		__overlay__ {
			#address-cells = <0x02>;
			#size-cells = <0x02>;

			wcn_reserved: wcn-mem@87000000 {
				reg = <0x00 0x87000000 0x00 0x800000>;
				phandle = <0x1e>;
			};

			logo_reserved: logobuffer@9e000000 {
				reg = <0x00 0x9e000000 0x00 0xab0000>;
				phandle = <0x0b>;
			};

			widevine_reserved: widevine@e3800000 {
				reg = <0x00 0xe3800000 0x00 0xc800000>;
				phandle = <0x13>;
			};

			fd_reserved: faceid-mem@ffa70000 {
				reg = <0x00 0xffa70000 0x00 0x500000>;
				phandle = <0x14>;
			};
		};
	};

	fragment@3 {
		target = <&thm_zone>;

		__overlay__ {

			bd_thmzone: board-thmzone {
				polling-delay-passive = <0x00>;
				polling-delay = <0x00>;
				thermal-sensors = <&tboard_thermistor>;
				phandle = <0x1f>;
			};

			pa_thmzone: pa-thmzone {
				polling-delay-passive = <0x00>;
				polling-delay = <0x00>;
				thermal-sensors = <&pa_thermistor>;
				phandle = <0x20>;
			};

			chg_thmzone: chg-thmzone {
				polling-delay-passive = <0x00>;
				polling-delay = <0x00>;
				thermal-sensors = <&chg_thermistor>;
				phandle = <0x21>;
			};
		};
	};

	fragment@4 {
		target = <&i2c0>;

		__overlay__ {
			status = "okay";
			clock-frequency = <0x61a80>;
			#address-cells = <0x01>;
			#size-cells = <0x00>;

			sensor_main: sensor-main@20 {
				compatible = "sprd,sensor-main";
				reg = <0x20>;
				clock-names = "clk_src", "sensor_eb", "clk_96m", "clk_76m8", "clk_48m", "clk_26m";
				clocks = <&mm_clk>, <0x02>, <&mm_gate>, <0x0d>, <&pll1>, <0x04>, <&pll1>, <0x10>, <&pll1>, <0x05>, <&ext_26m>;
				vddio-supply = <&vddcamio>;
				vddcama-supply = <&vddcama0>;
				vddcamd-supply = <&vddcamd0>;
				vddcammot-supply = <&vddcammot>;
				reset-gpios = <&ap_gpio>, <0x2c 0x00>;
				power-down-gpios = <&ap_gpio>, <0x2e 0x00>;
				sprd,phyid = <0x00>;
				csi = <&csi0>;
				power-domains = <&mm_domain>;
				phandle = <0x22>;
			};

			sensor_sub: sensor-sub@21 {
				compatible = "sprd,sensor-sub";
				reg = <0x21>;
				clock-names = "clk_src", "sensor_eb", "clk_96m", "clk_76m8", "clk_48m", "clk_26m";
				clocks = <&mm_clk>, <0x04>, <&mm_gate>, <0x0b>, <&pll1>, <0x04>, <&pll1>, <0x10>, <&pll1>, <0x05>, <&ext_26m>;
				vddio-supply = <&vddcamio>;
				vddcama-supply = <&vddcama0>;
				vddcamd-supply = <&vddcamd0>;
				vddcammot-supply = <&vddcammot>;
				reset-gpios = <&ap_gpio>, <0x29 0x00>;
				power-down-gpios = <&ap_gpio>, <0x28 0x00>;
				sprd,phyid = <0x02>;
				csi = <&csi0>;
				power-domains = <&mm_domain>;
				phandle = <0x23>;
			};
		};
	};

	fragment@5 {
		target = <&i2c1>;

		__overlay__ {
			status = "okay";
			clock-frequency = <0x61a80>;
			#address-cells = <0x01>;
			#size-cells = <0x00>;

			sensor_main2: sensor-main2@20 {
				compatible = "sprd,sensor-main2";
				reg = <0x20>;
				clock-names = "clk_src", "sensor_eb", "clk_96m", "clk_76m8", "clk_48m", "clk_26m";
				clocks = <&mm_clk>, <0x03>, <&mm_gate>, <0x0c>, <&pll1>, <0x04>, <&pll1>, <0x10>, <&pll1>, <0x05>, <&ext_26m>;
				vddio-supply = <&vddcamio>;
				vddcama-supply = <&vddcama1>;
				vddcamd-supply = <&vddcamd0>;
				vddcammot-supply = <&vddcammot>;
				avdd-gpios = <&ap_gpio>, <0x21 0x00>;
				mot-gpios = <&ap_gpio>, <0x58 0x00>;
				reset-gpios = <&ap_gpio>, <0x2d 0x00>;
				power-down-gpios = <&ap_gpio>, <0x2f 0x00>;
				sprd,phyid = <0x03>;
				csi = <&csi1>;
				power-domains = <&mm_domain>;
				phandle = <0x24>;
			};
		};
	};

	fragment@6 {
		target = <&i2c5>;

		__overlay__ {
			status = "okay";
			clock-frequency = <0x61a80>;
			#address-cells = <0x01>;
			#size-cells = <0x00>;

			bq2560x_chg: charger@6b {
				compatible = "ti,bq2560x_chg";
				reg = <0x6b>;
				phys = <&hsphy>;
				monitored-battery = <&bat>;
				extcon = <&pmic_typec>, <&pmic_pd>;
				pd-extcon-enable;
				phandle = <0x25>;

				vddvbus: otg-vbus {
					regulator-name = "vddvbus";
					phandle = <0x09>;
				};
			};

			flash_ic: flash-ic@63 {
				compatible = "sprd,flash-ocp8137";
				reg = <0x63>;
				sprd,flash-ic = <0x1fc9>;
				sprd,torch = <0x01>;
				sprd,preflash = <0x01>;
				sprd,highlight = <0x01>;
				sprd,torch-level = <0x80>;
				sprd,preflash-level = <0x80>;
				sprd,highlight-level = <0x80>;
				sprd,lvfm-enable = <0x01>;
				flash-torch-en-gpios = <&ap_gpio>, <0x20 0x00>;
				flash-chip-en-gpios = <&ap_gpio>, <0x8a 0x00>;
				flash-en-gpios = <&ap_gpio>, <0x8b 0x00>;
				phandle = <0x26>;
			};
		};
	};

	fragment@7 {
		target = <&i2c6>;

		__overlay__ {
			status = "disabled";
			clock-frequency = <0x61a80>;
			#address-cells = <0x01>;
			#size-cells = <0x00>;

			sensor_sub2: sensor-sub2@6e {
				compatible = "sprd,sensor-sub2";
				reg = <0x6e>;
				clock-names = "clk_src", "sensor_eb", "clk_96m", "clk_76m8", "clk_48m", "clk_26m";
				clocks = <&mm_clk>, <0x04>, <&mm_gate>, <0x0b>, <&pll1>, <0x04>, <&pll1>, <0x10>, <&pll1>, <0x05>, <&ext_26m>;
				vddio-supply = <&vddcamio>;
				avdd-gpios = <&ap_gpio>, <0x82 0x00>;
				vddcamd-supply = <&vddcamd1>;
				vddcammot-supply = <&vddcammot>;
				mot-gpios = <&ap_gpio>, <0x70 0x00>;
				reset-gpios = <&ap_gpio>, <0x72 0x00>;
				sprd,phyid = <0x03>;
				csi = <&csi2>;
				phandle = <0x27>;
			};
		};
	};

	fragment@8 {
		target = <&spi3>;

		__overlay__ {
			status = "okay";
			#address-cells = <0x01>;
			#size-cells = <0x00>;

			focaltech_ts_spi@0 {
				reg = <0x00>;
				status = "okay";
				spi-max-frequency = <0x927c00>;
				compatible = "focaltech,focaltech_ts_spi";
				focaltech,reset-gpio = <&ap_gpio>, <0x91 0x00>;
				focaltech,irq-gpio = <&ap_gpio>, <0x90 0x00>;
				vdd_name = "vdd28";
				focaltech,display-coords = <0x00 0x00 0x4af 0x77f>;
				virtualkeys = <0x50 0x384 0x1e 0x1e 0xf0 0x384 0x1e 0x1e 0x190 0x384 0x1e 0x1e>;
				TP_MAX_X = <0x4b0>;
				TP_MAX_Y = <0x780>;
			};

			himax_ts@1 {
				status = "okay";
				compatible = "himax,hxcommon";
				reg = <0x01>;
				spi-max-frequency = <0x989680>;
				spi-cpha;
				himax,panel-coords = <0x00 0x4b0 0x00 0x780>;
				himax,display-coords = <0x00 0x4b0 0x00 0x780>;
				himax,irq-gpio = <&ap_gpio>, <0x90 0x00>;
				himax,rst-gpio = <&ap_gpio>, <0x91 0x00>;
				report_type = <0x01>;
			};
		};
	};

	fragment@9 {
		target = <&dvfs_dcdc_cpu0_cfg>;

		__overlay__ {
			pmic-type-num = <0x00>;
			slew-rate = <0x249f>;
			tuning-latency-us = <0x00>;
		};
	};

	fragment@10 {
		target = <&dvfs_dcdc_cpu1_cfg>;

		__overlay__ {
			chnl-i2c-used;
			third-pmic-used;
			pmic-type-num = <0x02>;
			slew-rate = <0xfa0>;
			tuning-latency-us = <0x00>;
		};
	};

	fragment@11 {
		target = <&hsphy>;

		__overlay__ {
			vdd-supply = <&vddusb33>;
			extcon = <&extcon_gpio>;
			sprd,hsphy-device-eye-pattern = <0x4f3d1c0>;
			sprd,hsphy-host-eye-pattern = <0x4f3d1c0>;
			status = "okay";
		};
	};

	fragment@12 {
		target = <&usb>;

		__overlay__ {
			extcon = <&extcon_gpio>, <&pmic_typec>;
			vbus-supply = <&vddvbus>;
			status = "okay";
		};
	};

	fragment@13 {
		target = <&sdio0>;

		__overlay__ {
			cd-gpios = <&eic_sync>, <0x23 0x00>;
		};
	};

	fragment@14 {
		target = <&i2c2>;

		__overlay__ {
			status = "okay";
			#address-cells = <0x01>;
			#size-cells = <0x00>;

			sec-nfc@27 {
				compatible = "sec-nfc";
				reg = <0x27>;
				clock-names = "nfc_clk", "source", "enable";
				clocks = <&aon_clk>, <0x04>, <&ext_26m>, <&aonapb_gate>, <0x06>;
				sec-nfc,ven-gpio = <&ap_gpio>, <0x3f 0x00>;
				sec-nfc,firm-gpio = <&ap_gpio>, <0x3d 0x00>;
				sec-nfc,irq-gpio = <&ap_gpio>, <0x3e 0x00>;
				sec-nfc,clk-req = <&ap_gpio>, <0x3c 0x00>;
			};
		};
	};

	fragment@15 {
		target = <&i2c3>;

		__overlay__ {
			status = "okay";
			#address-cells = <0x01>;
			#size-cells = <0x00>;

			himax_ts@48 {
				status = "disabled";
				compatible = "himax,hxcommon";
				reg = <0x48>;
				himax,panel-coords = <0x00 0x4b0 0x00 0x780>;
				himax,display-coords = <0x00 0x4b0 0x00 0x780>;
				himax,irq-gpio = <&ap_gpio>, <0x90 0x00>;
				himax,rst-gpio = <&ap_gpio>, <0x91 0x00>;
				report_type = <0x01>;
			};
		};
	};

	fragment@16 {
		target = <&i2c4>;

		__overlay__ {
			status = "okay";
			#address-cells = <0x01>;
			#size-cells = <0x00>;

			aw87xxx_pa_58: pa@58 {
				compatible = "awinic,aw87xxx_pa";
				reg = <0x58>;
				#sound-dai-cells = <0x00>;
				dev_index = <0x00>;
				phandle = <0x28>;
			};

			aw87xxx_pa_59: pa@59 {
				compatible = "awinic,aw87xxx_pa";
				reg = <0x59>;
				#sound-dai-cells = <0x00>;
				dev_index = <0x01>;
				phandle = <0x29>;
			};

			aw87xxx_pa_5a: pa@5a {
				compatible = "awinic,aw87xxx_pa";
				reg = <0x5a>;
				#sound-dai-cells = <0x00>;
				dev_index = <0x02>;
				phandle = <0x2a>;
			};

			aw87xxx_pa_5b: pa@5b {
				compatible = "awinic,aw87xxx_pa";
				reg = <0x5b>;
				#sound-dai-cells = <0x00>;
				dev_index = <0x03>;
				phandle = <0x2b>;
			};
		};
	};

	fragment@17 {
		target = <&aon_i2c0>;

		__overlay__ {
			#address-cells = <0x01>;
			#size-cells = <0x00>;
			status = "okay";
			clock-frequency = <0xf4240>;

			bq2560x_slave_chg: charger@6b {
				compatible = "ti,bq2560x_slave_chg";
				reg = <0x6b>;
				phys = <&hsphy>;
				monitored-battery = <&bat>;
				extcon = <&extcon_gpio>;
				enable-gpio = <&ap_gpio>, <0x53 0x00>;
				role-slave;
				phandle = <0x2c>;
			};
		};
	};

	fragment@18 {
		target = <&sprd_headset>;

		__overlay__ {
			status = "okay";
		};
	};

	fragment@19 {
		target = <&pdm_dmic>;

		__overlay__ {
			status = "okay";
		};
	};

	fragment@20 {
		target = <&sound_vbc_v4_sprd_codec>;

		__overlay__ {
			status = "okay";
			sprd-audio-card,routing = "HeadPhone Jack", "HP Pin", "Ext Spk", "HP Pin", "Ext Spk1", "HP Pin", "Ext Ear", "EAR Pin";
			sprd,spk-ext-pa-info = <0x00 0x00 0x01 0x00 0x01 0x00 0x01 0x00>;
			sprd,spk-ext-pa-gpio = <&ap_gpio>, <0x1a 0x00>, <&ap_gpio>, <0x1b 0x00>;
			extral-iic-pa = <0x04>;
		};
	};

	fragment@21 {
		target = <&vddldo0>;

		__overlay__ {
			regulator-always-on;
		};
	};

	fragment@22 {
		target = <&pmic_fgu>;

		__overlay__ {
			monitored-battery = <&bat>;
			sprd,calib-resistance-micro-ohms = <0x12f2>;
			sprd,comp-resistance-mohm = <0x14>;
			fgu-capacity-track;
			phys = <&hsphy>;
			sprd,relax-counter-threshold = <0x244>;
			sprd,relax-current-threshold = <0x1e>;
			sprd,capacity-sleep-calibration;
			sprd,capacity-boot-calibration;
			sprd,capacity-charge-cycle;
			sprd,basp;
		};
	};

	fragment@23 {
		target = <&panel>;

		__overlay__ {
			sprd,backlight = <&pwm_backlight>;
			avdd-gpio = <&ap_gpio>, <0x87 0x00>;
			avee-gpio = <&ap_gpio>, <0x88 0x00>;
			reset-gpio = <&ap_gpio>, <0x32 0x00>;
		};
	};

	fragment@24 {
		target = <&dpu>;

		__overlay__ {
			sprd,logo-memory = <&logo_reserved>;
			sprd,backlight = <&pwm_backlight>;
		};
	};

	fragment@25 {
		target = <&pmic_fchg>;

		__overlay__ {
			status = "okay";
			sprd,input-voltage-microvolt = <0x4c4b40>;
			sprd,pd-fixed-max-microwatt = <0x112a880>;
			sprd,support-sfcp;
			phys = <&hsphy>;
		};
	};

	fragment@26 {
		target = <&pmic_pd>;

		__overlay__ {
			status = "okay";

			usb_con: connector {
				compatible = "usb-c-connector";
				label = "USB-C";
				power-role = "dual";
				try-power-role = "sink";
				source-pdos = <0x4019028>;
				sink-pdos = <0x401912c 0xc0dc213c>;
				op-sink-microwatt = <0x989680>;
				phandle = <0x2d>;
			};
		};
	};

	fragment@27 {
		target = <&ddr_dfs>;

		__overlay__ {
			sprd-scene = "boost", "lcdon", "lcdoff", "camlow", "camhigh", "camveryhigh", "faceid", "top";
			sprd-freq = <0x535 0x300 0x100 0x535 0x535 0x600 0x535 0x600>;
		};
	};

	fragment@28 {
		target = <&pin_controller>;

		__overlay__ {
			pinctrl-names = "gpio_8", "gpio_22", "gpio_24", "gpio_25", "gpio_26", "gpio_124", "gpio_175";
			pinctrl-0 = <&gpio_8>;
			pinctrl-1 = <&gpio_22>;
			pinctrl-2 = <&gpio_24>;
			pinctrl-3 = <&gpio_25>;
			pinctrl-4 = <&gpio_26>;
			pinctrl-5 = <&gpio_124>;
			pinctrl-6 = <&gpio_175>;

			gpio_8: rfctl16 {
				pins = "QOGIRL6_RFCTL16";
				function = "func4";
				phandle = <0x0c>;
			};

			gpio_22: rfctl3 {
				pins = "QOGIRL6_RFCTL3";
				function = "func4";
				phandle = <0x0d>;
			};

			gpio_24: rfctl5 {
				pins = "QOGIRL6_RFCTL5";
				function = "func4";
				phandle = <0x0e>;
			};

			gpio_25: rfctl6 {
				pins = "QOGIRL6_RFCTL6";
				function = "func4";
				phandle = <0x0f>;
			};

			gpio_26: rfctl7 {
				pins = "QOGIRL6_RFCTL7";
				function = "func4";
				phandle = <0x10>;
			};

			gpio_124: keyin0 {
				pins = "QOGIRL6_KEYIN0";
				function = "func4";
				phandle = <0x11>;
			};

			gpio_175: bt_rfctl2 {
				pins = "QOGIRL6_BT_RFCTL2";
				function = "func4";
				phandle = <0x12>;
			};
		};
	};

	fragment@29 {
		target = <&ion>;

		__overlay__ {
			#address-cells = <0x01>;
			#size-cells = <0x00>;

			heap@1 {
				reg = <0x01>;
				label = "carveout_mm";
				type = <0x02>;
				memory-region = <&widevine_reserved>;
			};

			heap@4 {
				reg = <0x04>;
				label = "carveout_fd";
				type = <0x02>;
				memory-region = <&fd_reserved>;
			};
		};
	};

	fragment@30 {
		target = <&adi_bus>;

		__overlay__ {
			sprd,hw-channels = <0x02 0x18cc 0x03 0x18cc 0x0d 0x1854 0x0f 0x1874 0x11 0x1844 0x13 0x1844 0x15 0x1864 0x1e 0x1820 0x20 0x197c 0x21 0x1988 0x23 0x19b8 0x27 0x19ac>;
		};
	};

	__symbols__ {
		lcd_hx8310_mipi = "/fragment/__overlay__/lcds/lcd_hx8310_mipi";
		lcd_ums512_xy_hsd_hx83102_mipi_fhd_timing0 = "/fragment/__overlay__/lcds/lcd_hx8310_mipi/display-timings/timing0";
		lcd_ums9230_dj_qc_ft8201ab_10_51_mipi = "/fragment/__overlay__/lcds/lcd_ums9230_dj_qc_ft8201ab_10_51_mipi";
		lcd_ums9230_dj_qc_ft8201ab_10_51_mipi_timing0 = "/fragment/__overlay__/lcds/lcd_ums9230_dj_qc_ft8201ab_10_51_mipi/display-timings/timing0";
		lcd_ums512_ft8201_hsd_ld_10_51cun_2k_mipi = "/fragment/__overlay__/lcds/lcd_ums512_ft8201_hsd_ld_10_51cun_2k_mipi";
		lcd_ums512_ld_ft8201_10_51_cun_2k_mipi_timing0 = "/fragment/__overlay__/lcds/lcd_ums512_ft8201_hsd_ld_10_51cun_2k_mipi/display-timings/timing0";
		lcd_dummy_mipi_hd = "/fragment/__overlay__/lcds/lcd_dummy_mipi_hd";
		dummy_timing0 = "/fragment/__overlay__/lcds/lcd_dummy_mipi_hd/display-timings/timing0";
		wcn_btwf = "/fragment/__overlay__/cpwcn-btwf";
		wcn_gnss = "/fragment/__overlay__/cpwcn-gnss";
		pwm_backlight = "/fragment/__overlay__/sprd_backlight";
		bat = "/fragment/__overlay__/battery";
		tboard_thermistor = "/fragment/__overlay__/thermal-sensor";
		pa_thermistor = "/fragment/__overlay__/pa-sensor";
		chg_thermistor = "/fragment/__overlay__/chg-sensor";
		sipc_wcn = "/fragment@0/__overlay__/core@3";
		sipc_gnss = "/fragment@0/__overlay__/core@4";
		sttygnss0 = "/fragment@0/__overlay__/core@4/channel@4";
		wcn_reserved = "/fragment@2/__overlay__/wcn-mem@87000000";
		logo_reserved = "/fragment@2/__overlay__/logobuffer@9e000000";
		widevine_reserved = "/fragment@2/__overlay__/widevine@e3800000";
		fd_reserved = "/fragment@2/__overlay__/faceid-mem@ffa70000";
		bd_thmzone = "/fragment@3/__overlay__/board-thmzone";
		pa_thmzone = "/fragment@3/__overlay__/pa-thmzone";
		chg_thmzone = "/fragment@3/__overlay__/chg-thmzone";
		sensor_main = "/fragment@4/__overlay__/sensor-main@20";
		sensor_sub = "/fragment@4/__overlay__/sensor-sub@21";
		sensor_main2 = "/fragment@5/__overlay__/sensor-main2@20";
		bq2560x_chg = "/fragment@6/__overlay__/charger@6b";
		vddvbus = "/fragment@6/__overlay__/charger@6b/otg-vbus";
		flash_ic = "/fragment@6/__overlay__/flash-ic@63";
		sensor_sub2 = "/fragment@7/__overlay__/sensor-sub2@6e";
		aw87xxx_pa_58 = "/fragment@16/__overlay__/pa@58";
		aw87xxx_pa_59 = "/fragment@16/__overlay__/pa@59";
		aw87xxx_pa_5a = "/fragment@16/__overlay__/pa@5a";
		aw87xxx_pa_5b = "/fragment@16/__overlay__/pa@5b";
		bq2560x_slave_chg = "/fragment@17/__overlay__/charger@6b";
		usb_con = "/fragment@26/__overlay__/connector";
		gpio_8 = "/fragment@28/__overlay__/rfctl16";
		gpio_22 = "/fragment@28/__overlay__/rfctl3";
		gpio_24 = "/fragment@28/__overlay__/rfctl5";
		gpio_25 = "/fragment@28/__overlay__/rfctl6";
		gpio_26 = "/fragment@28/__overlay__/rfctl7";
		gpio_124 = "/fragment@28/__overlay__/keyin0";
		gpio_175 = "/fragment@28/__overlay__/bt_rfctl2";
	};

	__fixups__ {
		aon_apb_regs = "/fragment/__overlay__/cpwcn-btwf:sprd,syscon-ap-apb:0", "/fragment/__overlay__/cpwcn-gnss:sprd,syscon-ap-apb:0";
		pmu_apb_regs = "/fragment/__overlay__/cpwcn-btwf:sprd,syscon-ap-pmu:0", "/fragment/__overlay__/cpwcn-gnss:sprd,syscon-ap-pmu:0";
		wcncp_aon_apb_regs = "/fragment/__overlay__/cpwcn-btwf:sprd,syscon-wcn-aon-apb:0", "/fragment/__overlay__/cpwcn-gnss:sprd,syscon-wcn-aon-apb:0";
		wcncp_aon_ahb_regs = "/fragment/__overlay__/cpwcn-btwf:sprd,syscon-wcn-aon-ahb:0", "/fragment/__overlay__/cpwcn-gnss:sprd,syscon-wcn-aon-ahb:0";
		pub_apb_regs = "/fragment/__overlay__/cpwcn-btwf:sprd,syscon-ap-pub-apb:0", "/fragment/__overlay__/cpwcn-gnss:sprd,syscon-ap-pub-apb:0";
		wcncp_btwf_ahb_regs = "/fragment/__overlay__/cpwcn-btwf:sprd,syscon-wcn-btwf-ahb:0";
		vddwcn = "/fragment/__overlay__/cpwcn-btwf:vddwcn-supply:0", "/fragment/__overlay__/cpwcn-gnss:vddwcn-supply:0";
		vddsim2 = "/fragment/__overlay__/cpwcn-btwf:dcxo1v8-supply:0", "/fragment/__overlay__/cpwcn-gnss:dcxo1v8-supply:0";
		vddwifipa = "/fragment/__overlay__/cpwcn-btwf:vddwifipa-supply:0";
		ap_gpio = "/fragment/__overlay__/cpwcn-btwf:merlion-chip-en-gpios:0", "/fragment/__overlay__/cpwcn-btwf:merlion-rst-gpios:0", "/fragment/__overlay__/cpwcn-btwf:xtal-26m-type-sel-gpios:0", "/fragment/__overlay__/cpwcn-gnss:merlion-chip-en-gpios:0", "/fragment/__overlay__/cpwcn-gnss:merlion-rst-gpios:0", "/fragment/__overlay__/cpwcn-gnss:xtal-26m-type-sel-gpios:0", "/fragment/__overlay__/sprd_backlight:hall-gpio:0", "/fragment/__overlay__/gpio-keys/key-volumedown:gpios:0", "/fragment/__overlay__/gpio-keys/key-volumeup:gpios:0", "/fragment/__overlay__/audio-voice-trig:irq_gpio:0", "/fragment@4/__overlay__/sensor-main@20:reset-gpios:0", "/fragment@4/__overlay__/sensor-main@20:power-down-gpios:0", "/fragment@4/__overlay__/sensor-sub@21:reset-gpios:0", "/fragment@4/__overlay__/sensor-sub@21:power-down-gpios:0", "/fragment@5/__overlay__/sensor-main2@20:avdd-gpios:0", "/fragment@5/__overlay__/sensor-main2@20:mot-gpios:0", "/fragment@5/__overlay__/sensor-main2@20:reset-gpios:0", "/fragment@5/__overlay__/sensor-main2@20:power-down-gpios:0", "/fragment@6/__overlay__/flash-ic@63:flash-torch-en-gpios:0", "/fragment@6/__overlay__/flash-ic@63:flash-chip-en-gpios:0", "/fragment@6/__overlay__/flash-ic@63:flash-en-gpios:0", "/fragment@7/__overlay__/sensor-sub2@6e:avdd-gpios:0", "/fragment@7/__overlay__/sensor-sub2@6e:mot-gpios:0", "/fragment@7/__overlay__/sensor-sub2@6e:reset-gpios:0", "/fragment@8/__overlay__/focaltech_ts_spi@0:focaltech,reset-gpio:0", "/fragment@8/__overlay__/focaltech_ts_spi@0:focaltech,irq-gpio:0", "/fragment@8/__overlay__/himax_ts@1:himax,irq-gpio:0", "/fragment@8/__overlay__/himax_ts@1:himax,rst-gpio:0", "/fragment@14/__overlay__/sec-nfc@27:sec-nfc,ven-gpio:0", "/fragment@14/__overlay__/sec-nfc@27:sec-nfc,firm-gpio:0", "/fragment@14/__overlay__/sec-nfc@27:sec-nfc,irq-gpio:0", "/fragment@14/__overlay__/sec-nfc@27:sec-nfc,clk-req:0", "/fragment@15/__overlay__/himax_ts@48:himax,irq-gpio:0", "/fragment@15/__overlay__/himax_ts@48:himax,rst-gpio:0", "/fragment@17/__overlay__/charger@6b:enable-gpio:0", "/fragment@20/__overlay__:sprd,spk-ext-pa-gpio:0", "/fragment@20/__overlay__:sprd,spk-ext-pa-gpio:12", "/fragment@23/__overlay__:avdd-gpio:0", "/fragment@23/__overlay__:avee-gpio:0", "/fragment@23/__overlay__:reset-gpio:0";
		wcn_alpha = "/fragment/__overlay__/cpwcn-btwf:nvmem-cells:0", "/fragment/__overlay__/cpwcn-gnss:nvmem-cells:0";
		wcncp_gnss_ahb_regs = "/fragment/__overlay__/cpwcn-gnss:sprd,syscon-wcn-gnss-ahb:0";
		pwms = "/fragment/__overlay__/sprd_backlight:pwms:0";
		eic_async = "/fragment/__overlay__/fingerprint@0:fpint-gpios:0";
		pmic_eic = "/fragment/__overlay__/gpio-keys/key-power:gpios:0";
		pmic_typec = "/fragment/__overlay__/charger-manager/regulator@0/cable@0:extcon:0", "/fragment@6/__overlay__/charger@6b:extcon:0", "/fragment@12/__overlay__:extcon:4";
		pmic_adc = "/fragment/__overlay__/thermal-sensor:io-channels:0", "/fragment/__overlay__/pa-sensor:io-channels:0", "/fragment/__overlay__/chg-sensor:io-channels:0";
		uid_start = "/fragment/__overlay__/sprd_uid:nvmem-cells:0";
		uid_end = "/fragment/__overlay__/sprd_uid:nvmem-cells:4";
		sipc = "/fragment@0:target:0";
		mailbox = "/fragment@0/__overlay__/core@3:mboxes:0", "/fragment@0/__overlay__/core@4:mboxes:0";
		chosen = "/fragment@1:target:0";
		reserved_memory = "/fragment@2:target:0";
		thm_zone = "/fragment@3:target:0";
		i2c0 = "/fragment@4:target:0";
		mm_clk = "/fragment@4/__overlay__/sensor-main@20:clocks:0", "/fragment@4/__overlay__/sensor-sub@21:clocks:0", "/fragment@5/__overlay__/sensor-main2@20:clocks:0", "/fragment@7/__overlay__/sensor-sub2@6e:clocks:0";
		mm_gate = "/fragment@4/__overlay__/sensor-main@20:clocks:8", "/fragment@4/__overlay__/sensor-sub@21:clocks:8", "/fragment@5/__overlay__/sensor-main2@20:clocks:8", "/fragment@7/__overlay__/sensor-sub2@6e:clocks:8";
		pll1 = "/fragment@4/__overlay__/sensor-main@20:clocks:16", "/fragment@4/__overlay__/sensor-main@20:clocks:24", "/fragment@4/__overlay__/sensor-main@20:clocks:32", "/fragment@4/__overlay__/sensor-sub@21:clocks:16", "/fragment@4/__overlay__/sensor-sub@21:clocks:24", "/fragment@4/__overlay__/sensor-sub@21:clocks:32", "/fragment@5/__overlay__/sensor-main2@20:clocks:16", "/fragment@5/__overlay__/sensor-main2@20:clocks:24", "/fragment@5/__overlay__/sensor-main2@20:clocks:32", "/fragment@7/__overlay__/sensor-sub2@6e:clocks:16", "/fragment@7/__overlay__/sensor-sub2@6e:clocks:24", "/fragment@7/__overlay__/sensor-sub2@6e:clocks:32";
		ext_26m = "/fragment@4/__overlay__/sensor-main@20:clocks:40", "/fragment@4/__overlay__/sensor-sub@21:clocks:40", "/fragment@5/__overlay__/sensor-main2@20:clocks:40", "/fragment@7/__overlay__/sensor-sub2@6e:clocks:40", "/fragment@14/__overlay__/sec-nfc@27:clocks:8";
		vddcamio = "/fragment@4/__overlay__/sensor-main@20:vddio-supply:0", "/fragment@4/__overlay__/sensor-sub@21:vddio-supply:0", "/fragment@5/__overlay__/sensor-main2@20:vddio-supply:0", "/fragment@7/__overlay__/sensor-sub2@6e:vddio-supply:0";
		vddcama0 = "/fragment@4/__overlay__/sensor-main@20:vddcama-supply:0", "/fragment@4/__overlay__/sensor-sub@21:vddcama-supply:0";
		vddcamd0 = "/fragment@4/__overlay__/sensor-main@20:vddcamd-supply:0", "/fragment@4/__overlay__/sensor-sub@21:vddcamd-supply:0", "/fragment@5/__overlay__/sensor-main2@20:vddcamd-supply:0";
		vddcammot = "/fragment@4/__overlay__/sensor-main@20:vddcammot-supply:0", "/fragment@4/__overlay__/sensor-sub@21:vddcammot-supply:0", "/fragment@5/__overlay__/sensor-main2@20:vddcammot-supply:0", "/fragment@7/__overlay__/sensor-sub2@6e:vddcammot-supply:0";
		csi0 = "/fragment@4/__overlay__/sensor-main@20:csi:0", "/fragment@4/__overlay__/sensor-sub@21:csi:0";
		mm_domain = "/fragment@4/__overlay__/sensor-main@20:power-domains:0", "/fragment@4/__overlay__/sensor-sub@21:power-domains:0", "/fragment@5/__overlay__/sensor-main2@20:power-domains:0";
		i2c1 = "/fragment@5:target:0";
		vddcama1 = "/fragment@5/__overlay__/sensor-main2@20:vddcama-supply:0";
		csi1 = "/fragment@5/__overlay__/sensor-main2@20:csi:0";
		i2c5 = "/fragment@6:target:0";
		hsphy = "/fragment@6/__overlay__/charger@6b:phys:0", "/fragment@11:target:0", "/fragment@17/__overlay__/charger@6b:phys:0", "/fragment@22/__overlay__:phys:0", "/fragment@25/__overlay__:phys:0";
		pmic_pd = "/fragment@6/__overlay__/charger@6b:extcon:4", "/fragment@26:target:0";
		i2c6 = "/fragment@7:target:0";
		vddcamd1 = "/fragment@7/__overlay__/sensor-sub2@6e:vddcamd-supply:0";
		csi2 = "/fragment@7/__overlay__/sensor-sub2@6e:csi:0";
		spi3 = "/fragment@8:target:0";
		dvfs_dcdc_cpu0_cfg = "/fragment@9:target:0";
		dvfs_dcdc_cpu1_cfg = "/fragment@10:target:0";
		vddusb33 = "/fragment@11/__overlay__:vdd-supply:0";
		extcon_gpio = "/fragment@11/__overlay__:extcon:0", "/fragment@12/__overlay__:extcon:0", "/fragment@17/__overlay__/charger@6b:extcon:0";
		usb = "/fragment@12:target:0";
		sdio0 = "/fragment@13:target:0";
		eic_sync = "/fragment@13/__overlay__:cd-gpios:0";
		i2c2 = "/fragment@14:target:0";
		aon_clk = "/fragment@14/__overlay__/sec-nfc@27:clocks:0";
		aonapb_gate = "/fragment@14/__overlay__/sec-nfc@27:clocks:12";
		i2c3 = "/fragment@15:target:0";
		i2c4 = "/fragment@16:target:0";
		aon_i2c0 = "/fragment@17:target:0";
		sprd_headset = "/fragment@18:target:0";
		pdm_dmic = "/fragment@19:target:0";
		sound_vbc_v4_sprd_codec = "/fragment@20:target:0";
		vddldo0 = "/fragment@21:target:0";
		pmic_fgu = "/fragment@22:target:0";
		panel = "/fragment@23:target:0";
		dpu = "/fragment@24:target:0";
		pmic_fchg = "/fragment@25:target:0";
		ddr_dfs = "/fragment@27:target:0";
		pin_controller = "/fragment@28:target:0";
		ion = "/fragment@29:target:0";
		adi_bus = "/fragment@30:target:0";
	};

	__local_fixups__ {

		fragment {

			__overlay__ {

				lcds {

					lcd_hx8310_mipi {

						display-timings {
							native-mode = <0x00>;
						};
					};

					lcd_ums9230_dj_qc_ft8201ab_10_51_mipi {

						display-timings {
							native-mode = <0x00>;
						};
					};

					lcd_ums512_ft8201_hsd_ld_10_51cun_2k_mipi {

						display-timings {
							native-mode = <0x00>;
						};
					};

					lcd_dummy_mipi_hd {

						display-timings {
							native-mode = <0x00>;
						};
					};
				};

				charger-manager {
					monitored-battery = <0x00>;
				};
			};
		};

		fragment@3 {

			__overlay__ {

				board-thmzone {
					thermal-sensors = <0x00>;
				};

				pa-thmzone {
					thermal-sensors = <0x00>;
				};

				chg-thmzone {
					thermal-sensors = <0x00>;
				};
			};
		};

		fragment@6 {

			__overlay__ {

				charger@6b {
					monitored-battery = <0x00>;
				};
			};
		};

		fragment@12 {

			__overlay__ {
				vbus-supply = <0x00>;
			};
		};

		fragment@17 {

			__overlay__ {

				charger@6b {
					monitored-battery = <0x00>;
				};
			};
		};

		fragment@22 {

			__overlay__ {
				monitored-battery = <0x00>;
			};
		};

		fragment@23 {

			__overlay__ {
				sprd,backlight = <0x00>;
			};
		};

		fragment@24 {

			__overlay__ {
				sprd,logo-memory = <0x00>;
				sprd,backlight = <0x00>;
			};
		};

		fragment@28 {

			__overlay__ {
				pinctrl-0 = <0x00>;
				pinctrl-1 = <0x00>;
				pinctrl-2 = <0x00>;
				pinctrl-3 = <0x00>;
				pinctrl-4 = <0x00>;
				pinctrl-5 = <0x00>;
				pinctrl-6 = <0x00>;
			};
		};

		fragment@29 {

			__overlay__ {

				heap@1 {
					memory-region = <0x00>;
				};

				heap@4 {
					memory-region = <0x00>;
				};
			};
		};
	};
};
